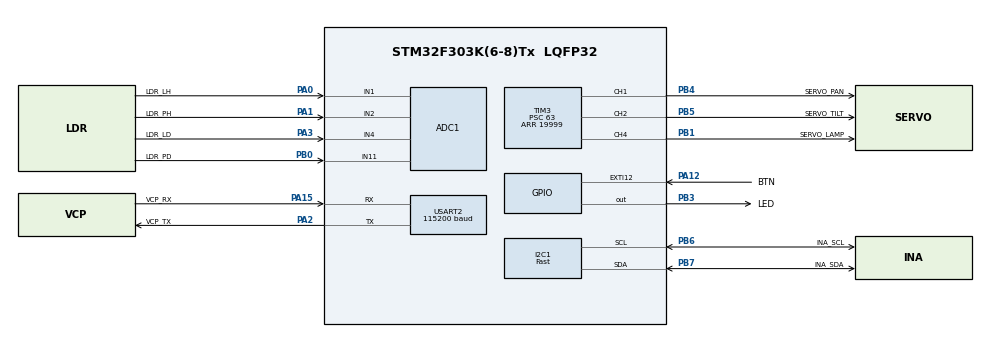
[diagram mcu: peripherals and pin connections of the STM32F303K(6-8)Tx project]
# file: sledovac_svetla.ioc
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ADC1.Channel-0\#ChannelRegularConversion=ADC_CHANNEL_1
ADC1.Channel-1\#ChannelRegularConversion=ADC_CHANNEL_2
ADC1.Channel-2\#ChannelRegularConversion=ADC_CHANNEL_4
ADC1.Channel-3\#ChannelRegularConversion=ADC_CHANNEL_11
ADC1.DMAContinuousRequests=ENABLE
ADC1.EOCSelection=ADC_EOC_SEQ_CONV
ADC1.EnableInjectedConversion=DISABLE
ADC1.ExternalTrigConv=ADC_EXTERNALTRIGCONV_T2_TRGO
ADC1.NbrOfConversion=4
ADC1.NbrOfConversionFlag=1
ADC1.Offset-0\#ChannelRegularConversion=0
ADC1.Offset-1\#ChannelRegularConversion=0
ADC1.Offset-2\#ChannelRegularConversion=0
ADC1.Offset-3\#ChannelRegularConversion=0
ADC1.OffsetNumber-0\#ChannelRegularConversion=ADC_OFFSET_NONE
ADC1.OffsetNumber-1\#ChannelRegularConversion=ADC_OFFSET_NONE
ADC1.OffsetNumber-2\#ChannelRegularConversion=ADC_OFFSET_NONE
ADC1.OffsetNumber-3\#ChannelRegularConversion=ADC_OFFSET_NONE
ADC1.Rank-0\#ChannelRegularConversion=1
ADC1.Rank-1\#ChannelRegularConversion=2
ADC1.Rank-2\#ChannelRegularConversion=3
ADC1.Rank-3\#ChannelRegularConversion=4
ADC1.SamplingTime-0\#ChannelRegularConversion=ADC_SAMPLETIME_181CYCLES_5
ADC1.SamplingTime-1\#ChannelRegularConversion=ADC_SAMPLETIME_181CYCLES_5
ADC1.SamplingTime-2\#ChannelRegularConversion=ADC_SAMPLETIME_181CYCLES_5
ADC1.SamplingTime-3\#ChannelRegularConversion=ADC_SAMPLETIME_181CYCLES_5
ADC1.SamplingTimeOPAMP-1\#ChannelRegularConversion=ADC_SAMPLETIME_61CYCLES_5
ADC1.SamplingTimeOPAMP-2\#ChannelRegularConversion=ADC_SAMPLETIME_61CYCLES_5
ADC1.SamplingTimeOPAMP-3\#ChannelRegularConversion=ADC_SAMPLETIME_61CYCLES_5
ADC1.SubFamily=STM32F303x8
ADC1.master=1
Dma.ADC1.0.Direction=DMA_PERIPH_TO_MEMORY
Dma.ADC1.0.Instance=DMA1_Channel1
Dma.ADC1.0.MemDataAlignment=DMA_MDATAALIGN_HALFWORD
Dma.ADC1.0.MemInc=DMA_MINC_ENABLE
Dma.ADC1.0.Mode=DMA_CIRCULAR
Dma.ADC1.0.PeriphDataAlignment=DMA_PDATAALIGN_HALFWORD
Dma.ADC1.0.PeriphInc=DMA_PINC_DISABLE
Dma.ADC1.0.Priority=DMA_PRIORITY_HIGH
Dma.Request0=ADC1
I2C1.I2C_Speed_Mode=I2C_Fast
I2C1.Timing=0x0010020A
Mcu.Family=STM32F3
Mcu.Name=STM32F303K(6-8)Tx
Mcu.Package=LQFP32
NVIC.DMA1_Channel1_IRQn=true\:2\:0\:true\:false\:true\:false\:true\:true
NVIC.EXTI15_10_IRQn=true\:3\:0\:true\:false\:true\:true\:true\:true
NVIC.PriorityGroup=NVIC_PRIORITYGROUP_4
NVIC.TIM6_DAC1_IRQn=true\:2\:0\:true\:false\:true\:true\:true\:true
NVIC.USART2_IRQn=true\:1\:0\:true\:false\:true\:true\:true\:true
PA0.GPIO_Label=LDR_LH
PA0.Mode=IN1-Single-Ended
PA0.Signal=ADC1_IN1
PA1.GPIO_Label=LDR_PH
PA1.Mode=IN2-Single-Ended
PA1.Signal=ADC1_IN2
PA12.GPIO_Label=BTN
PA12.GPIO_ModeDefaultEXTI=GPIO_MODE_IT_FALLING
PA12.GPIO_PuPd=GPIO_PULLUP
PA12.Signal=GPXTI12
PA13.GPIO_Label=SWDIO
PA13.Mode=Serial_Wire
PA13.Signal=SYS_JTMS-SWDIO
PA14.GPIO_Label=SWCLK
PA14.Mode=Serial_Wire
PA14.Signal=SYS_JTCK-SWCLK
PA15.GPIO_Label=VCP_RX
PA15.Mode=Asynchronous
PA15.Signal=USART2_RX
PA2.GPIO_Label=VCP_TX
PA2.Mode=Asynchronous
PA2.Signal=USART2_TX
PA3.GPIO_Label=LDR_LD
PA3.Mode=IN4-Single-Ended
PA3.Signal=ADC1_IN4
PB0.GPIO_Label=LDR_PD
PB0.Mode=IN11-Single-Ended
PB0.Signal=ADC1_IN11
PB1.GPIO_Label=SERVO_LAMP
PB1.Signal=S_TIM3_CH4
PB3.GPIO_Label=LED
PB3.Signal=GPIO_Output
PB4.GPIO_Label=SERVO_PAN
PB4.Signal=S_TIM3_CH1
PB5.GPIO_Label=SERVO_TILT
PB5.Signal=S_TIM3_CH2
PB6.GPIO_Label=INA_SCL
PB6.GPIO_Pu=GPIO_NOPULL
PB6.Mode=I2C
PB6.Signal=I2C1_SCL
PB7.GPIO_Label=INA_SDA
PB7.GPIO_Pu=GPIO_NOPULL
PB7.Mode=I2C
PB7.Signal=I2C1_SDA
ProjectManager.HeapSize=0x200
ProjectManager.StackSize=0x400
ProjectManager.TargetToolchain=STM32CubeIDE
RCC.AHBFreq_Value=64000000
RCC.APB1CLKDivider=RCC_HCLK_DIV2
RCC.APB1Freq_Value=32000000
RCC.APB1TimFreq_Value=64000000
RCC.APB2Freq_Value=64000000
RCC.APB2TimFreq_Value=64000000
RCC.CortexFreq_Value=64000000
RCC.HCLKFreq_Value=64000000
RCC.HSE_VALUE=8000000
RCC.HSI_VALUE=8000000
RCC.PLLMUL=RCC_PLL_MUL16
RCC.SYSCLKFreq_VALUE=64000000
RCC.SYSCLKSourceVirtual=RCC_SYSCLKSOURCE_PLLCLK
SH.S_TIM3_CH1.0=TIM3_CH1,PWM Generation1 CH1
SH.S_TIM3_CH2.0=TIM3_CH2,PWM Generation2 CH2
SH.S_TIM3_CH4.0=TIM3_CH4,PWM Generation4 CH4
TIM2.AutoReloadPreload=TIM_AUTORELOAD_PRELOAD_ENABLE
TIM2.Period=999
TIM2.Prescaler=63
TIM2.TIM_MasterOutputTrigger=TIM_TRGO_UPDATE
TIM3.AutoReloadPreload=TIM_AUTORELOAD_PRELOAD_ENABLE
TIM3.Channel-PWM\ Generation1\ CH1=TIM_CHANNEL_1
TIM3.Channel-PWM\ Generation2\ CH2=TIM_CHANNEL_2
TIM3.Channel-PWM\ Generation4\ CH4=TIM_CHANNEL_4
TIM3.Period=19999
TIM3.Prescaler=63
TIM3.Pulse-PWM\ Generation1\ CH1=1500
TIM3.Pulse-PWM\ Generation2\ CH2=1500
TIM3.Pulse-PWM\ Generation4\ CH4=1500
TIM6.AutoReloadPreload=TIM_AUTORELOAD_PRELOAD_ENABLE
TIM6.Period=19999
TIM6.Prescaler=63
USART2.BaudRate=115200
USART2.VirtualMode-Asynchronous=VM_ASYNC
VP_TIM2_VS_ClockSourceINT.Mode=Internal
VP_TIM3_VS_ClockSourceINT.Mode=Internal
VP_TIM6_VS_ClockSourceINT.Mode=Enable_Timer
board=NUCLEO-F303K8

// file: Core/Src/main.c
/* USER CODE BEGIN Header */
/**
  ******************************************************************************
  * @file           : main.c
  * @brief          : Main program body
  ******************************************************************************
  * @attention
  *
  * Copyright (c) 2026 STMicroelectronics.
  * All rights reserved.
  *
  * This software is licensed under terms that can be found in the LICENSE file
  * in the root directory of this software component.
  * If no LICENSE file comes with this software, it is provided AS-IS.
  *
  ******************************************************************************
  */
/* USER CODE END Header */
#include "main.h"
#include "adc.h"
#include "dma.h"
#include "i2c.h"
#include "tim.h"
#include "usart.h"
#include "gpio.h"

/* USER CODE BEGIN Includes */
#include "comm.h"
#include "fsm.h"
#include "control.h"
#include "testrig.h"
/* USER CODE END Includes */

void SystemClock_Config(void);

/* USER CODE BEGIN 0 */
/* docasny test dosky (krok 4), v kroku 5 ho nahradi fsm_tick() */

/* USER CODE END 0 */

int main(void)
{

  /* MCU Configuration--------------------------------------------------------*/

  /* Reset of all peripherals, Initializes the Flash interface and the Systick. */
  LL_APB2_GRP1_EnableClock(LL_APB2_GRP1_PERIPH_SYSCFG);
  LL_APB1_GRP1_EnableClock(LL_APB1_GRP1_PERIPH_PWR);

  /* System interrupt init*/
  NVIC_SetPriorityGrouping(NVIC_PRIORITYGROUP_4);

  /* Configure the system clock */
  SystemClock_Config();

  /* Initialize all configured peripherals */
  MX_GPIO_Init();
  MX_DMA_Init();
  MX_USART2_UART_Init();
  MX_ADC1_Init();
  MX_TIM2_Init();
  MX_TIM3_Init();
  MX_I2C1_Init();
  MX_TIM6_Init();
  /* USER CODE BEGIN 2 */
  comm_init();
  control_init();
   testrig_init();
  fsm_init();
  comm_send("#EV START\r\n");

  /* USER CODE END 2 */

  /* Infinite loop */
  while (1)
  {

    /* USER CODE BEGIN 3 */
	  comm_process();
	      fsm_process();
  }
  /* USER CODE END 3 */
}

void SystemClock_Config(void)
{
  LL_FLASH_SetLatency(LL_FLASH_LATENCY_2);
  while(LL_FLASH_GetLatency()!= LL_FLASH_LATENCY_2)
  {
  }
  LL_RCC_HSI_Enable();

   /* Wait till HSI is ready */
  while(LL_RCC_HSI_IsReady() != 1)
  {

  }
  LL_RCC_HSI_SetCalibTrimming(16);
  LL_RCC_PLL_ConfigDomain_SYS(LL_RCC_PLLSOURCE_HSI_DIV_2, LL_RCC_PLL_MUL_16);
  LL_RCC_PLL_Enable();

   /* Wait till PLL is ready */
  while(LL_RCC_PLL_IsReady() != 1)
  {

  }
  LL_RCC_SetAHBPrescaler(LL_RCC_SYSCLK_DIV_1);
  LL_RCC_SetAPB1Prescaler(LL_RCC_APB1_DIV_2);
  LL_RCC_SetAPB2Prescaler(LL_RCC_APB2_DIV_1);
  LL_RCC_SetSysClkSource(LL_RCC_SYS_CLKSOURCE_PLL);

   /* Wait till System clock is ready */
  while(LL_RCC_GetSysClkSource() != LL_RCC_SYS_CLKSOURCE_STATUS_PLL)
  {

  }
  LL_Init1msTick(64000000);
  LL_SetSystemCoreClock(64000000);
  LL_RCC_SetI2CClockSource(LL_RCC_I2C1_CLKSOURCE_HSI);
  LL_RCC_SetADCClockSource(LL_RCC_ADC12_CLKSRC_PLL_DIV_1);
}

void Error_Handler(void)
{
  __disable_irq();
  while (1)
  {
  }
}
